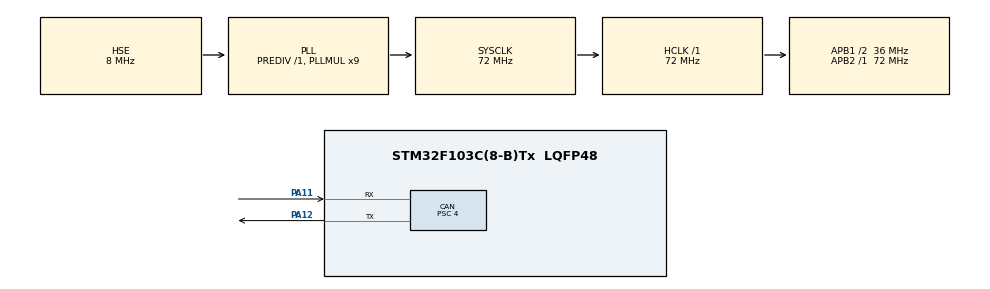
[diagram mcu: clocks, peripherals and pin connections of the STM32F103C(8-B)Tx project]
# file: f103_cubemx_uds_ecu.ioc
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CAN.ABOM=ENABLE
CAN.BS1=CAN_BS1_15TQ
CAN.BS2=CAN_BS2_2TQ
CAN.CalculateBaudRate=500000
CAN.CalculateTimeBit=2000
CAN.CalculateTimeQuantum=111.11111111111111
CAN.NART=DISABLE
CAN.Prescaler=4
Mcu.Family=STM32F1
Mcu.Name=STM32F103C(8-B)Tx
Mcu.Package=LQFP48
NVIC.PriorityGroup=NVIC_PRIORITYGROUP_4
PA11.Mode=CAN_Activate
PA11.Signal=CAN_RX
PA12.Mode=CAN_Activate
PA12.Signal=CAN_TX
PD0-OSC_IN.Mode=HSE-External-Oscillator
PD0-OSC_IN.Signal=RCC_OSC_IN
PD1-OSC_OUT.Mode=HSE-External-Oscillator
PD1-OSC_OUT.Signal=RCC_OSC_OUT
ProjectManager.HeapSize=0x200
ProjectManager.StackSize=0x400
ProjectManager.TargetToolchain=Makefile
RCC.AHBFreq_Value=72000000
RCC.APB1CLKDivider=RCC_HCLK_DIV2
RCC.APB1Freq_Value=36000000
RCC.APB1TimFreq_Value=72000000
RCC.APB2Freq_Value=72000000
RCC.HCLKFreq_Value=72000000
RCC.PLLMUL=RCC_PLL_MUL9
RCC.SYSCLKFreq_VALUE=72000000
RCC.SYSCLKSource=RCC_SYSCLKSOURCE_PLLCLK
RCC.USBFreq_Value=72000000
VP_CRC_VS_CRC.Mode=CRC_Activate
board=custom

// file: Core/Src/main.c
/* USER CODE BEGIN Header */
/*
 * Copyright (c) 2026 Andrii Shylenko
 * SPDX-License-Identifier: PolyForm-Noncommercial-1.0.0
 *
 * STM32F103C8 (Blue Pill) UDS ECU over bxCAN. CubeMX-style scaffold: peripheral
 * init here, the UDS reprogramming logic in uds_ecu_app.c. CAN1 on PA11/PA12 at
 * 500 kbit/s; 72 MHz from an 8 MHz HSE.
 */
/* USER CODE END Header */

#include "main.h"
/* USER CODE BEGIN Includes */
#include "uds_ecu_app.h"
/* USER CODE END Includes */

CAN_HandleTypeDef hcan;
CRC_HandleTypeDef hcrc;

void SystemClock_Config(void);
static void MX_GPIO_Init(void);
static void MX_CAN_Init(void);
static void MX_CRC_Init(void);

int main(void)
{
    HAL_Init();
    SystemClock_Config();

    MX_GPIO_Init();
    MX_CRC_Init();
    MX_CAN_Init();

    /* USER CODE BEGIN 2 */
    uds_app_init(&hcan, &hcrc);
    /* USER CODE END 2 */

    while (1) {
        /* USER CODE BEGIN WHILE */
        uds_app_poll();
        /* USER CODE END WHILE */
    }
}

void SystemClock_Config(void)
{
    RCC_OscInitTypeDef osc = {0};
    RCC_ClkInitTypeDef clk = {0};

    osc.OscillatorType = RCC_OSCILLATORTYPE_HSE;
    osc.HSEState = RCC_HSE_ON;
    osc.HSEPredivValue = RCC_HSE_PREDIV_DIV1;
    osc.PLL.PLLState = RCC_PLL_ON;
    osc.PLL.PLLSource = RCC_PLLSOURCE_HSE;
    osc.PLL.PLLMUL = RCC_PLL_MUL9;
    if (HAL_RCC_OscConfig(&osc) != HAL_OK) {
        Error_Handler();
    }

    clk.ClockType =
        RCC_CLOCKTYPE_HCLK | RCC_CLOCKTYPE_SYSCLK | RCC_CLOCKTYPE_PCLK1 | RCC_CLOCKTYPE_PCLK2;
    clk.SYSCLKSource = RCC_SYSCLKSOURCE_PLLCLK;
    clk.AHBCLKDivider = RCC_SYSCLK_DIV1;
    clk.APB1CLKDivider = RCC_HCLK_DIV2; /* 36 MHz */
    clk.APB2CLKDivider = RCC_HCLK_DIV1; /* 72 MHz */
    if (HAL_RCC_ClockConfig(&clk, FLASH_LATENCY_2) != HAL_OK) {
        Error_Handler();
    }
}

/**
 * @brief CAN1 init: 500 kbit/s at 36 MHz APB1 (prescaler 4, 1+15+2 = 18 tq).
 */
static void MX_CAN_Init(void)
{
    hcan.Instance = CAN1;
    hcan.Init.Prescaler = 4;
    hcan.Init.Mode = CAN_MODE_NORMAL;
    hcan.Init.SyncJumpWidth = CAN_SJW_1TQ;
    hcan.Init.TimeSeg1 = CAN_BS1_15TQ;
    hcan.Init.TimeSeg2 = CAN_BS2_2TQ;
    hcan.Init.TimeTriggeredMode = DISABLE;
    hcan.Init.AutoBusOff = ENABLE;
    hcan.Init.AutoWakeUp = DISABLE;
    hcan.Init.AutoRetransmission = ENABLE;
    hcan.Init.ReceiveFifoLocked = DISABLE;
    hcan.Init.TransmitFifoPriority = DISABLE;
    if (HAL_CAN_Init(&hcan) != HAL_OK) {
        Error_Handler();
    }
}

static void MX_CRC_Init(void)
{
    hcrc.Instance = CRC;
    if (HAL_CRC_Init(&hcrc) != HAL_OK) {
        Error_Handler();
    }
}

static void MX_GPIO_Init(void)
{
    __HAL_RCC_GPIOA_CLK_ENABLE();
}

void Error_Handler(void)
{
    __disable_irq();
    while (1) {
    }
}
